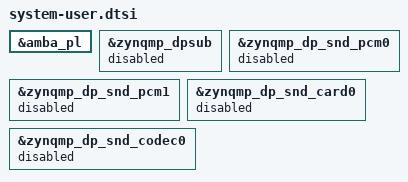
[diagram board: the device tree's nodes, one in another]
/include/ "system-conf.dtsi"


/* Remove all PL definitions, for use with FPGA-MANAGER */
&amba_pl {
  /delete-node/ system_management_wiz@a0090000;
  /delete-node/ axi_apio_1;
  /delete-node/ axi_gpio_2;
  /delete-node/ zyxclmm_drm;
};

&zynqmp_dpsub {
	status = "disabled";
};

&zynqmp_dp_snd_pcm0 {
	status = "disabled";
};

&zynqmp_dp_snd_pcm1 {
	status = "disabled";
};

&zynqmp_dp_snd_card0 {
	status = "disabled";
};

&zynqmp_dp_snd_codec0 {
	status = "disabled";
};

/*
&amba {
	zocl: zyxclmm_drm {
		compatible = "xlnx,zocl";
		status = "okay";
		interrupt-parent = <&gic>;
		interrupts = <0 89  4>, <0 90  4>, <0 91  4>, <0 92  4>,
			     <0 93  4>, <0 94  4>, <0 95  4>, <0 96  4>;
	};
};
*/



